# GD32F1x0 register map
File version: 1.0
CPU: CM3 r2p1, little endian, no MPU, no FPU, 4 interrupt priority bits
Registers are 32-bit, read-write, reset 0x0 unless marked. A register's access mark holds for its fields unless they carry their own. Offsets are from the block's base; [hi:lo] are bit positions; {n}, {i} and the like mark numbered series.

## FMC
Base 0x40022000
0x00 WS — Wait state register
  [2:0] WSCNT — Wait state counter register
0x04 KEY wo — Flash unlock key register
  [31:0] KEY — FMC_CTL unlock registers
0x08 OBKEY wo — Flash option byte unlock key register
  [31:0] OBKEY — FMC_CTL option byte operation unlock registers
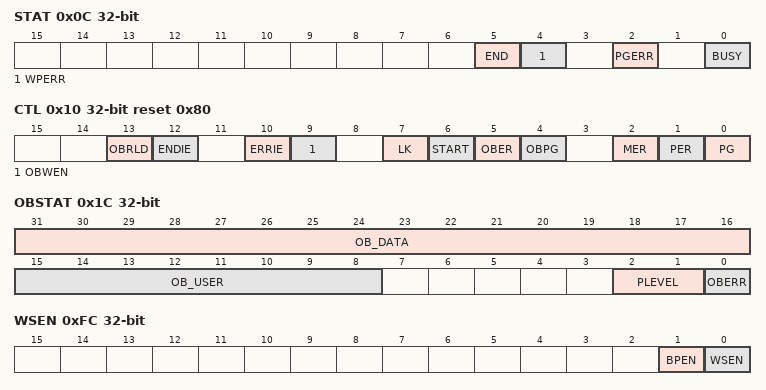
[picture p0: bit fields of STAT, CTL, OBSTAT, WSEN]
0x0C STAT access per field — Flash status register
  [5] END rw — End of operation flag bit
  [4] WPERR rw — Erase/Program protection error flag bit
  [2] PGERR rw — Program error flag bit
  [0] BUSY ro — The flash busy bit
0x10 CTL reset 0x80 — Flash control register
  [13] OBRLD — Option byte reload bit
  [12] ENDIE — End of operation interrupt enable
  [10] ERRIE — Error interrupt enable
  [9] OBWEN — Option byte erase/program enable bit
  [7] LK — FMC_CTL lock bit
  [6] START — Send erase command to FMC bit
  [5] OBER — Option byte erase command bit
  [4] OBPG — Option byte program command bit
  [2] MER — Main flash mass erase command bit
  [1] PER — Main flash page erase command bit
  [0] PG — Main flash page program command bit
0x14 ADDR — Flash address register
  [31:0] ADDR — Flash command address
0x1C OBSTAT ro — Option byte status register
  [31:16] OB_DATA — Store OB_DATA[15:0] of option byte block after system reset
  [15:8] OB_USER — Store OB_USER byte of option byte block after system reset
  [2:1] PLEVEL — Security Protection level
  [0] OBERR — Option byte read error
0x20 WP ro — Write protection register
  [15:0] OB_WP — Store OB_WP[15:0] of option byte block after system reset
0xFC WSEN — Flash wait state control register
  [1] BPEN — FMC bit program enable register
  [0] WSEN — FMC wait state enable register
0x100 PID ro — Flash Product ID register
  [31:0] PID — Product reserved ID code register1

## FWDGT — free watchdog timer
Base 0x40003000
0x00 CTL wo — Control register
  [15:0] CMD — Key value
0x04 PSC — Prescaler register
  [2:0] PSC — Free watchdog timer prescaler selection
0x08 RLD reset 0xFFF — Reload register
  [11:0] RLD — Free watchdog timer counter reload value
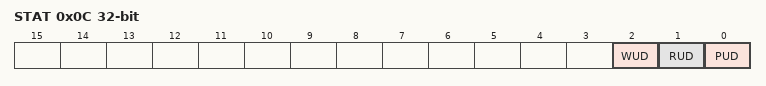
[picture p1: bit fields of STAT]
0x0C STAT ro — Status register
  [2] WUD — Watchdog counter window value update
  [1] RUD — Free watchdog timer counter reload value update
  [0] PUD — Free watchdog timer prescaler value update
0x10 WND reset 0xFFF — Window register
  [11:0] WND — Watchdog counter window value

## GPIOA — General-purpose I/Os
Base 0x48000000
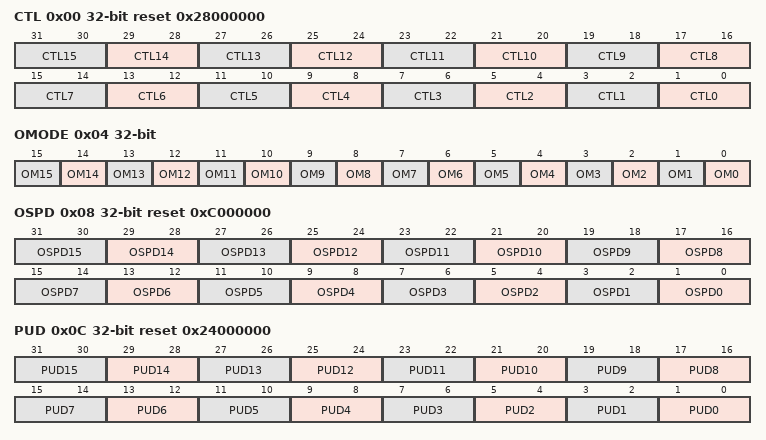
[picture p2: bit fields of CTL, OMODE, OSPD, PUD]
0x00 CTL reset 0x28000000 — GPIO port control register
  [2n+1:2n] CTL{n} (n=0..15) — Pin {n} configuration bits
0x04 OMODE — GPIO port output type register
  [n] OM{n} (n=0..15) — Pin {n} output mode
0x08 OSPD reset 0xC000000 — GPIO port output speed register
  [2n+1:2n] OSPD{n} (n=0..15) — Pin {n} output max speed bits
0x0C PUD reset 0x24000000 — GPIO port pull-up/pull-down register
  [2n+1:2n] PUD{n} (n=0..15) — Pin {n} pull-up or pull-down bits
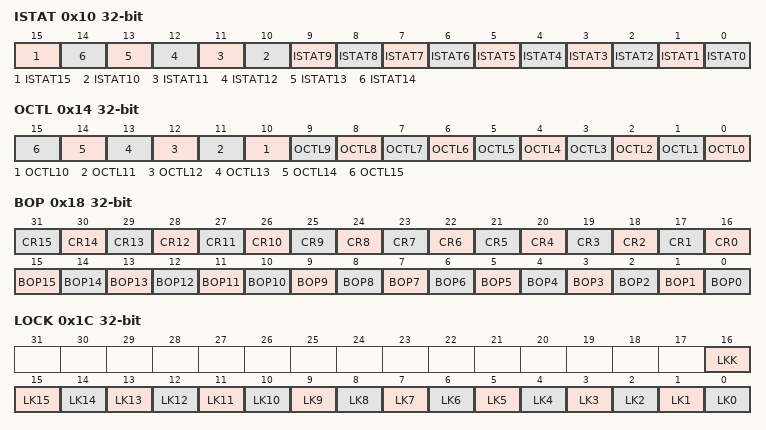
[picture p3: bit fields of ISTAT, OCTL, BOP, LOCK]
0x10 ISTAT ro — GPIO port input data register
  [15] ISTAT15 — Port input data 14
  [n] ISTAT{n} (n=0..14) — Port input data {n}
0x14 OCTL — GPIO port output data register
  [n] OCTL{n} (n=0..15) — Port output data {n}
0x18 BOP wo — GPIO port bit set/reset register
  [n+16] CR{n} (n=0..15) — Port reset bit {n}
  [15] BOP15 — Port set bit15
  [n] BOP{n} (n=0..14) — Port set bit {n}
0x1C LOCK — GPIO port configuration lock register
  [16] LKK — Lock key
  [n] LK{n} (n=0..15) — Port lock bit {n}
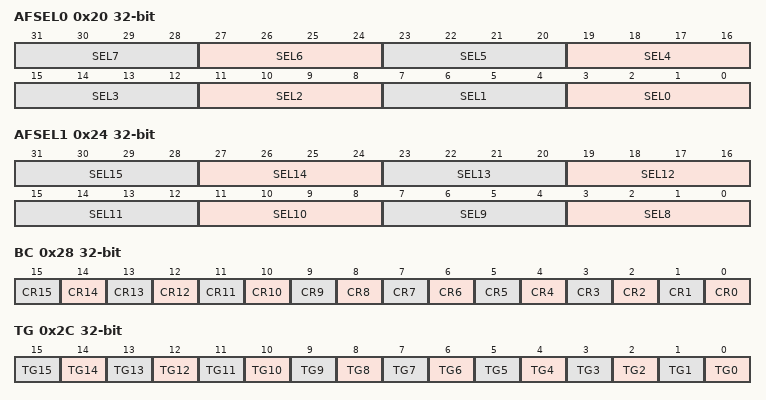
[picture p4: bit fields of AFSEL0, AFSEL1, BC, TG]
0x20 AFSEL0 — GPIO alternate function low register
  [4n+3:4n] SEL{n} (n=0..7) — Pin {n} alternate function selected
0x24 AFSEL1 — GPIO alternate function register 1
  [4n-29:4n-32] SEL{n} (n=8..15) — Pin {n} alternate function selected
0x28 BC wo — Port bit reset register
  [n] CR{n} (n=0..15) — Port cleat bit {n}
0x2C TG wo — Port bit toggle register
  [n] TG{n} (n=0..15) — Port toggle bit {n}

## GPIOB — General-purpose I/Os
Base 0x48000400
Registers as GPIOA; these are added or differ:
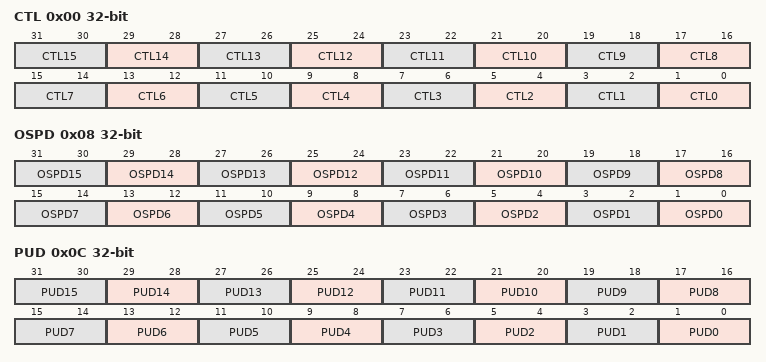
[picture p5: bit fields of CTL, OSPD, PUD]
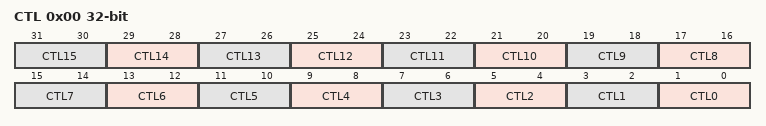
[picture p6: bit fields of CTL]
0x00 CTL — GPIO port control register
  [2n+1:2n] CTL{n} (n=0..15) — Pin {n} configuration bits
0x08 OSPD — GPIO port output speed register
  [2n+1:2n] OSPD{n} (n=0..15) — Pin {n} output max speed bits
0x0C PUD — GPIO port pull-up/pull-down register
  [2n+1:2n] PUD{n} (n=0..15) — Pin {n} pull-up or pull-down bits

## GPIOC — General-purpose I/Os
Base 0x48000800
Registers as GPIOB, without LOCK; these are added or differ:
0x00 CTL — GPIO port control register
  [2n+1:2n] CTL{n} (n=0..15) — Port x configuration bits (y = 0..15)

## GPIOD — General-purpose I/Os
Base 0x48000C00
Registers as GPIOC, without AFSEL0, AFSEL1.

## GPIOF — General-purpose I/Os
Base 0x48001400
Registers as GPIOB, without LOCK, AFSEL0, AFSEL1; these are added or differ:
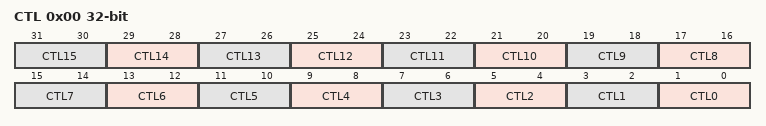
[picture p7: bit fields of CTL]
0x00 CTL — GPIOF port control register
  [2n+1:2n] CTL{n} (n=0..15) — Port x configuration bits (y = 0..15)
